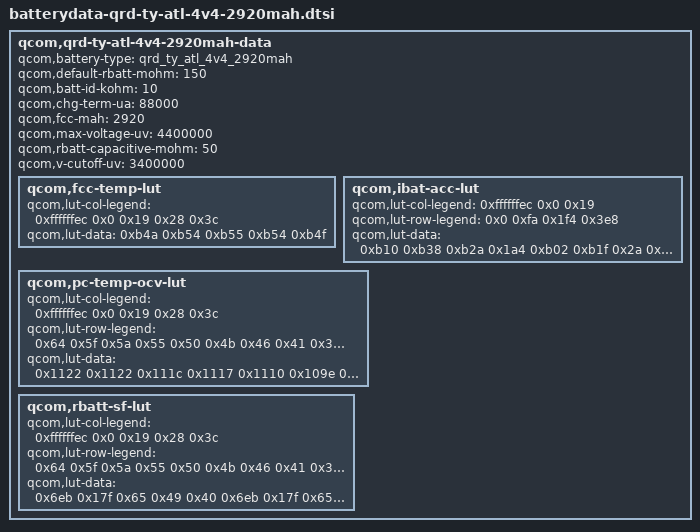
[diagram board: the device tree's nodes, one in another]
/* Copyright (c) 2020, The Linux Foundation. All rights reserved.
*  Copyright (c) 2020, the_shahnawaz_sheikh (sheikhshahnawaz41299).
*
* This program is free software; you can redistribute it and/or modify
* it under the terms of the GNU General Public License version 2 and
* only version 2 as published by the Free Software Foundation.
*
* This program is distributed in the hope that it will be useful,
* but WITHOUT ANY WARRANTY; without even the implied warranty of
* MERCHANTABILITY or FITNESS FOR A PARTICULAR PURPOSE.  See the
* GNU General Public License for more details.
*/

qcom,qrd-ty-atl-4v4-2920mah-data {
			qcom,battery-type = "qrd_ty_atl_4v4_2920mah";
			qcom,default-rbatt-mohm = <150>;
			qcom,batt-id-kohm = <10>;
			qcom,chg-term-ua = <88000>;
			qcom,fcc-mah = <2920>;
			qcom,max-voltage-uv = <4400000>;
			qcom,rbatt-capacitive-mohm = <50>;
			qcom,v-cutoff-uv = <3400000>;

			qcom,fcc-temp-lut {
				qcom,lut-col-legend = <0xffffffec 0x0 0x19 0x28 0x3c>;
				qcom,lut-data = <0xb4a 0xb54 0xb55 0xb54 0xb4f>;
			};

			qcom,ibat-acc-lut {
				qcom,lut-col-legend = <0xffffffec 0x0 0x19>;
				qcom,lut-row-legend = <0x0 0xfa 0x1f4 0x3e8>;
				qcom,lut-data = <0xb10 0xb38 0xb2a 0x1a4 0xb02 0xb1f 0x2a 0x9ac 0xb0d 0x6 0x6e0 0xae9>;
			};

			qcom,pc-temp-ocv-lut {
				qcom,lut-col-legend = <0xffffffec 0x0 0x19 0x28 0x3c>;
				qcom,lut-row-legend = <0x64 0x5f 0x5a 0x55 0x50 0x4b 0x46 0x41 0x3c 0x37 0x32 0x2d 0x28 0x23 0x1e 0x19 0x14 0x10 0xd 0xb 0xa 0x9 0x8 0x7 0x6 0x5 0x4 0x3 0x2 0x1>;
				qcom,lut-data = <0x1122 0x1122 0x111c 0x1117 0x1110 0x109e 0x10d6 0x10dd 0x10da 0x10d5 0x104a 0x1098 0x10a2 0x10a0 0x109c 0x100c 0x105e 0x1069 0x1067 0x1063 0xfdc 0x1026 0x1031 0x102f 0x102b 0xf81 0xff0 0xffa 0xffa 0xff6 0xf51 0xfb7 0xfca 0xfc8 0xfc4 0xf26 0xf74 0xf96 0xf98 0xf96 0xf06 0xf4d 0xf64 0xf68 0xf68 0xef2 0xf27 0xf32 0xf34 0xf32 0xee2 0xf07 0xf11 0xf12 0xf11 0xed5 0xeec 0xef7 0xef8 0xef6 0xec7 0xed6 0xee1 0xee2 0xee1 0xeba 0xec8 0xece 0xecf 0xece 0xeaa 0xebc 0xebd 0xebc 0xeb6 0xe9a 0xead 0xeaa 0xea4 0xe9a 0xe86 0xe9a 0xe98 0xe90 0xe84 0xe73 0xe86 0xe84 0xe7c 0xe6e 0xe62 0xe78 0xe70 0xe68 0xe5c 0xe52 0xe70 0xe68 0xe61 0xe56 0xe4a 0xe6c 0xe66 0xe60 0xe54 0xe42 0xe68 0xe64 0xe5e 0xe54 0xe37 0xe64 0xe62 0xe5c 0xe52 0xe2a 0xe5e 0xe60 0xe58 0xe4e 0xe18 0xe54 0xe58 0xe50 0xe42 0xe02 0xe3e 0xe40 0xe35 0xe24 0xde2 0xe18 0xe14 0xe08 0xdf6 0xdb2 0xde2 0xdd9 0xdcd 0xdba 0xd69 0xd94 0xd88 0xd7c 0xd6a 0xce8 0xd18 0xd0b 0xcfc 0xceb>;
			};

			qcom,rbatt-sf-lut {
				qcom,lut-col-legend = <0xffffffec 0x0 0x19 0x28 0x3c>;
				qcom,lut-row-legend = <0x64 0x5f 0x5a 0x55 0x50 0x4b 0x46 0x41 0x3c 0x37 0x32 0x2d 0x28 0x23 0x1e 0x19 0x14 0x10 0xd 0xb 0xa 0x9 0x8 0x7 0x6 0x5 0x4 0x3 0x2 0x1>;
				qcom,lut-data = <0x6eb 0x17f 0x65 0x49 0x40 0x6eb 0x17f 0x65 0x49 0x40 0x649 0x17f 0x65 0x4b 0x41 0x5e8 0x177 0x67 0x4c 0x41 0x5b8 0x171 0x69 0x4e 0x43 0x54c 0x16a 0x6c 0x50 0x45 0x537 0x165 0x72 0x54 0x47 0x527 0x145 0x77 0x58 0x49 0x525 0x147 0x70 0x5b 0x4c 0x537 0x140 0x62 0x4b 0x42 0x557 0x13f 0x5f 0x49 0x41 0x588 0x140 0x5f 0x4b 0x41 0x5c1 0x144 0x61 0x4d 0x44 0x5fc 0x14c 0x64 0x4f 0x46 0x639 0x15c 0x64 0x4f 0x44 0x671 0x176 0x61 0x4a 0x42 0x6b2 0x195 0x62 0x4b 0x41 0x710 0x1b0 0x63 0x4b 0x41 0x78f 0x1cc 0x63 0x49 0x41 0x7ef 0x1df 0x63 0x4a 0x41 0x7f7 0x1df 0x64 0x4b 0x42 0x79d 0x1db 0x65 0x4c 0x44 0x824 0x1ea 0x67 0x4e 0x46 0x8dd 0x1fc 0x6b 0x51 0x49 0x9c4 0x20f 0x6d 0x51 0x48 0xaf1 0x222 0x6c 0x4e 0x43 0xc82 0x239 0x69 0x4d 0x43 0xec8 0x263 0x6f 0x50 0x45 0x129c 0x2a1 0x75 0x55 0x4b 0x2538 0x37c 0x9f 0x77 0x5f>;
			};
		};
		
		
		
